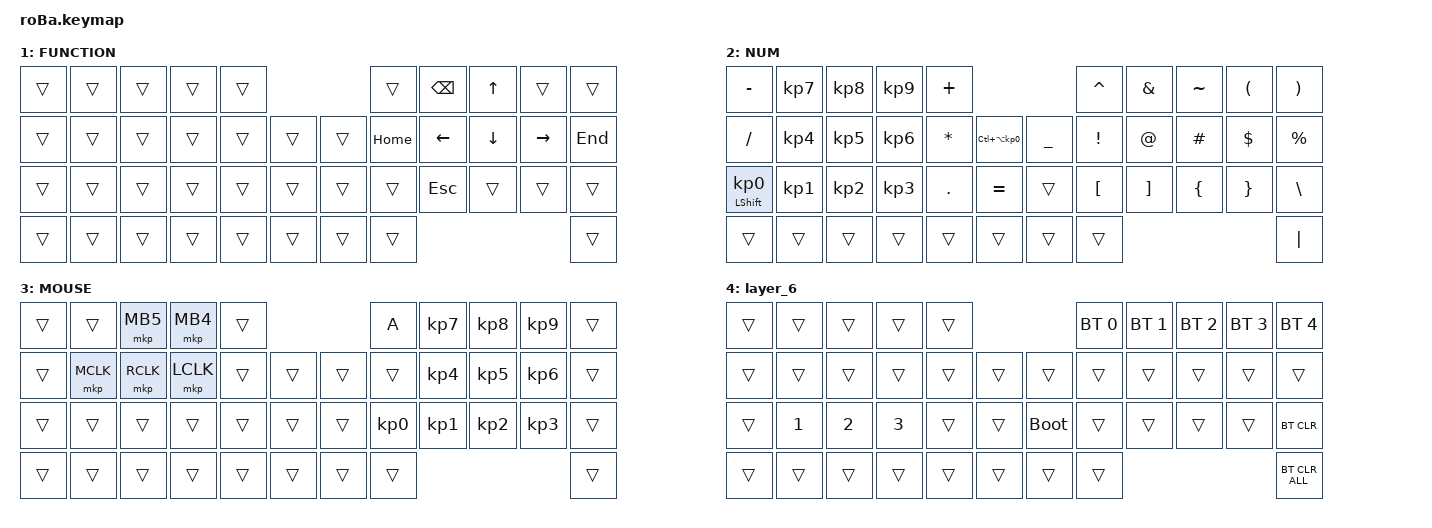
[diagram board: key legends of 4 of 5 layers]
#include <behaviors.dtsi>
#include <dt-bindings/zmk/bt.h>
#include <dt-bindings/zmk/keys.h>
#include <dt-bindings/zmk/pointing.h>

&mt {
    flavor = "balanced";
    quick-tap-ms = <0>;
};

&trackball {
    automouse-layer = <4>;
    scroll-layers = <5>;

    // arrows {
    //     layers = <3>;
    //     bindings =
    //         <&kp RIGHT_ARROW>,
    //         <&kp LEFT_ARROW>,
    //         <&kp UP_ARROW>,
    //         <&kp DOWN_ARROW>;
    //     tick = <10>;
    //     wait-ms = <5>;
    //     tap-ms = <5>;
    // };
};

/ {
    combos {
        compatible = "zmk,combos";

        tab {
            bindings = <&kp TAB>;
            key-positions = <11 12>;
        };

        shift_tab {
            bindings = <&kp LS(TAB)>;
            key-positions = <12 13>;
        };

        muhennkann {
            bindings = <&to_layer_0 INT_MUHENKAN>;
            key-positions = <11 10>;
        };

        double_quotation {
            bindings = <&kp DOUBLE_QUOTES>;
            key-positions = <20 21>;
        };

        eq {
            bindings = <&kp EQUAL>;
            key-positions = <24 25>;
        };
    };

    macros {
        to_layer_0: to_layer_0 {
            compatible = "zmk,behavior-macro-one-param";
            #binding-cells = <1>;
            bindings = <&to 0 &macro_param_1to1 &kp MACRO_PLACEHOLDER>;
            label = "TO_LAYER_0";
        };
    };

    behaviors {
        lt_to_layer_0: lt_to_layer_0 {
            compatible = "zmk,behavior-hold-tap";
            label = "LAYER_TAP_TO_0";
            bindings = <&mo>, <&to_layer_0>;

            #binding-cells = <2>;
            tapping-term-ms = <200>;
        };
    };

    keymap {
        compatible = "zmk,keymap";

        default_layer {
            bindings = <
&kp Q         &kp W         &kp E         &kp R         &kp T   &kp N9            &kp Z         &kp Y         &kp U  &kp I   &kp O         &kp P
&kp A         &kp S         &kp D         &kp F         &kp G   &kp N7            &kp NUMBER_1  &kp H         &kp J  &kp K   &kp L         &kp N7
&kp Z         &kp X         &kp C         &kp V         &kp B   &kp N8            &kp NUMBER_2  &kp N         &kp M  &kp N5  &kp NUMBER_6  &kp N8
&kp NUMBER_1  &kp NUMBER_2  &kp NUMBER_3  &kp NUMBER_4  &kp N5  &kp NUMBER_6      &kp NUMBER_3  &kp NUMBER_4                 &kp Z         &kp N9
            >;

            sensor-bindings = <&inc_dec_kp PG_UP PAGE_DOWN>;
        };

         FUNCTION {
             bindings = <
 &trans  &trans  &trans  &trans  &trans                      &trans    &kp BACKSPACE   &kp UP    &trans     &trans
 &trans  &trans  &trans  &trans  &trans  &trans      &trans  &kp HOME  &kp LEFT_ARROW  &kp DOWN  &kp RIGHT  &kp END
 &trans  &trans  &trans  &trans  &trans  &trans      &trans  &trans    &kp ESCAPE      &trans    &trans     &trans
 &trans  &trans  &trans  &trans  &trans  &trans      &trans  &trans                                         &trans
             >;
         };
 
         NUM {
             bindings = <
 &kp MINUS                   &kp KP_NUMBER_7  &kp KP_NUMBER_8  &kp KP_NUMBER_9  &kp PLUS                                                   &kp CARET         &kp AMPERSAND      &kp TILDE       &kp LEFT_PARENTHESIS  &kp RIGHT_PARENTHESIS
 &kp SLASH                   &kp KP_NUMBER_4  &kp KP_NUMBER_5  &kp KP_NUMBER_6  &kp ASTERISK  &kp LC(LA(KP_NUMBER_0))      &kp UNDERSCORE  &kp EXCLAMATION   &kp AT_SIGN        &kp HASH        &kp DOLLAR            &kp PERCENT
 &mt LEFT_SHIFT KP_NUMBER_0  &kp KP_NUMBER_1  &kp KP_NUMBER_2  &kp KP_NUMBER_3  &kp PERIOD    &kp EQUAL                    &trans          &kp LEFT_BRACKET  &kp RIGHT_BRACKET  &kp LEFT_BRACE  &kp RIGHT_BRACE       &kp BACKSLASH
 &trans                      &trans           &trans           &trans           &trans        &trans                       &trans          &trans                                                                     &kp PIPE
             >;
         };
 
         MOUSE {
             bindings = <
 &trans  &trans     &mkp MB5   &mkp MB4   &trans                      &kp A            &kp KP_NUMBER_7  &kp KP_NUMBER_8  &kp KP_NUMBER_9  &trans
 &trans  &mkp MCLK  &mkp RCLK  &mkp LCLK  &trans  &trans      &trans  &trans           &kp KP_NUMBER_4  &kp KP_NUMBER_5  &kp KP_NUMBER_6  &trans
 &trans  &trans     &trans     &trans     &trans  &trans      &trans  &kp KP_NUMBER_0  &kp KP_NUMBER_1  &kp KP_NUMBER_2  &kp KP_NUMBER_3  &trans
 &trans  &trans     &trans     &trans     &trans  &trans      &trans  &trans                                                              &trans
             >;
         };
 
         layer_6 {
             bindings = <
 &trans  &trans        &trans        &trans        &trans                           &bt BT_SEL 0  &bt BT_SEL 1  &bt BT_SEL 2  &bt BT_SEL 3  &bt BT_SEL 4
 &trans  &trans        &trans        &trans        &trans  &trans      &trans       &trans        &trans        &trans        &trans        &trans
 &trans  &kp NUMBER_1  &kp NUMBER_2  &kp NUMBER_3  &trans  &trans      &bootloader  &trans        &trans        &trans        &trans        &bt BT_CLR
 &trans  &trans        &trans        &trans        &trans  &trans      &trans       &trans                                                  &bt BT_CLR_ALL
             >;
         };
    };
};
